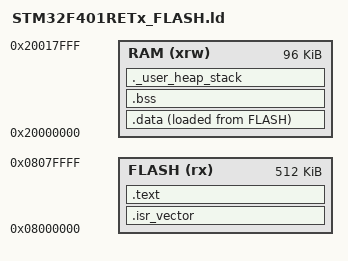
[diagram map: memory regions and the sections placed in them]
/* STM32F401RETx_FLASH.ld */
ENTRY(Reset_Handler)

_estack = ORIGIN(RAM) + LENGTH(RAM);

MEMORY
{
  RAM   (xrw) : ORIGIN = 0x20000000, LENGTH = 96K
  FLASH (rx)  : ORIGIN = 0x08000000, LENGTH = 512K
}

SECTIONS
{
  .isr_vector :
  {
    . = ALIGN(4);
    KEEP(*(.isr_vector))
    . = ALIGN(4);
  } >FLASH

  .text :
  {
    . = ALIGN(4);
    *(.text)
    *(.text*)
    *(.rodata)
    *(.rodata*)

    . = ALIGN(4);
    PROVIDE_HIDDEN (__preinit_array_start = .);
    KEEP (*(.preinit_array*))
    PROVIDE_HIDDEN (__preinit_array_end = .);

    . = ALIGN(4);
    PROVIDE_HIDDEN (__init_array_start = .);
    KEEP (*(SORT(.init_array.*)))
    KEEP (*(.init_array*))
    PROVIDE_HIDDEN (__init_array_end = .);

    . = ALIGN(4);
    PROVIDE_HIDDEN (__fini_array_start = .);
    KEEP (*(SORT(.fini_array.*)))
    KEEP (*(.fini_array*))
    PROVIDE_HIDDEN (__fini_array_end = .);

    . = ALIGN(4);
    _etext = .;
  } >FLASH

  .data :
  {
    . = ALIGN(4);
    _sdata = .;
    *(.data)
    *(.data*)
    . = ALIGN(4);
    _edata = .;
  } >RAM AT> FLASH

  _sidata = LOADADDR(.data);

  .bss :
  {
    . = ALIGN(4);
    _sbss = .;
    *(.bss)
    *(.bss*)
    *(COMMON)
    . = ALIGN(4);
    _ebss = .;
  } >RAM

  ._user_heap_stack :
  {
    . = ALIGN(8);
    PROVIDE(end = .);
    . = . + 0x400;   /* heap  1KB */
    . = . + 0x400;   /* stack 1KB */
    . = ALIGN(8);
  } >RAM
}
